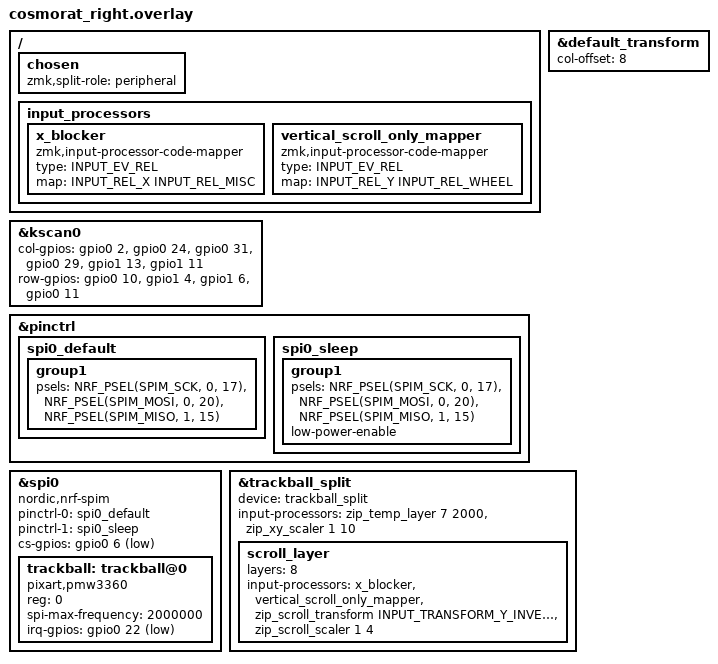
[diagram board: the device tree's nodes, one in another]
#include "cosmorat.dtsi"
#include <dt-bindings/input/input-event-codes.h>
#include <input/processors.dtsi>
#include <dt-bindings/zmk/input_transform.h>

/ {
    chosen {
        zmk,split-role = "peripheral";
    };
    input_processors {
        x_blocker: x_blocker {
            compatible = "zmk,input-processor-code-mapper";
            #input-processor-cells = <0>;
            type = <INPUT_EV_REL>;
            map = <INPUT_REL_X INPUT_REL_MISC>;
        };
        
        vertical_scroll_only_mapper: vertical_scroll_only_mapper {
            compatible = "zmk,input-processor-code-mapper";
            #input-processor-cells = <0>;
            type = <INPUT_EV_REL>;
            map = <INPUT_REL_Y INPUT_REL_WHEEL>;
        };
    };
};

&default_transform {
    col-offset = <8>;
};

&kscan0 {
    col-gpios
        = <&gpio0 2 GPIO_ACTIVE_HIGH>
        , <&gpio0 24 GPIO_ACTIVE_HIGH>
        , <&gpio0 31 GPIO_ACTIVE_HIGH>
        , <&gpio0 29 GPIO_ACTIVE_HIGH>
        , <&gpio1 13 GPIO_ACTIVE_HIGH>
        , <&gpio1 11 GPIO_ACTIVE_HIGH>
        ;

    row-gpios
        = <&gpio0 10 (GPIO_ACTIVE_HIGH | GPIO_PULL_DOWN)>
        , <&gpio1 4 (GPIO_ACTIVE_HIGH | GPIO_PULL_DOWN)>
        , <&gpio1 6 (GPIO_ACTIVE_HIGH | GPIO_PULL_DOWN)>
        , <&gpio0 11 (GPIO_ACTIVE_HIGH | GPIO_PULL_DOWN)>
        ;
};

&pinctrl {
    spi0_default: spi0_default {
        group1 {
            psels = <NRF_PSEL(SPIM_SCK, 0, 17)>,
                    <NRF_PSEL(SPIM_MOSI, 0, 20)>,
                    <NRF_PSEL(SPIM_MISO, 1, 15)>;
        };
    };
    spi0_sleep: spi0_sleep {
        group1 {
            psels = <NRF_PSEL(SPIM_SCK, 0, 17)>,
                    <NRF_PSEL(SPIM_MOSI, 0, 20)>,
                    <NRF_PSEL(SPIM_MISO, 1, 15)>;
            low-power-enable;
        };
    };
};

&spi0 {
    status = "okay";
    compatible = "nordic,nrf-spim";
    pinctrl-0 = <&spi0_default>;
    pinctrl-1 = <&spi0_sleep>;
    pinctrl-names = "default", "sleep";
    cs-gpios = <&gpio0 6 GPIO_ACTIVE_LOW>;

    trackball: trackball@0 {
        status = "okay";
        compatible = "pixart,pmw3360";
        reg = <0>;
        spi-max-frequency = <2000000>;
        irq-gpios = <&gpio0 22 (GPIO_ACTIVE_LOW | GPIO_PULL_UP)>;
    };
};

&trackball_split {
    status = "okay";
    device = <&trackball_split>;
    input-processors = <&zip_temp_layer 7 2000 &zip_xy_scaler 1 10>;

    scroll_layer {
        layers = <8>;
        input-processors = <&x_blocker &vertical_scroll_only_mapper &zip_scroll_transform INPUT_TRANSFORM_Y_INVERT &zip_scroll_scaler 1 4>;
    };
};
